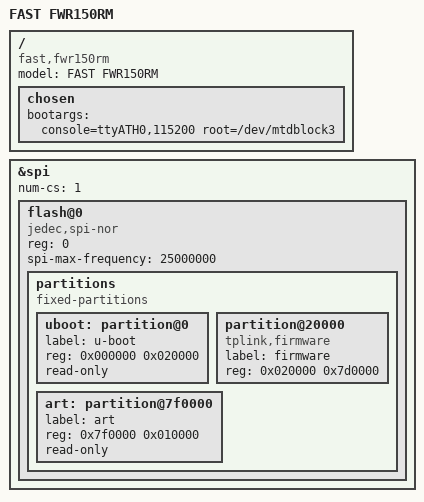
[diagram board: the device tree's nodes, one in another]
// SPDX-License-Identifier: GPL-2.0-or-later OR MIT

#include "ar9331_tplink_tl-wr710n.dtsi"

/ {
    model = "FAST FWR150RM";
    compatible = "fast,fwr150rm", "qca,ar9331";
    chosen {
        bootargs = "console=ttyATH0,115200 root=/dev/mtdblock3";
    };
};

&spi {
    status = "okay";
    num-cs = <1>;

    flash@0 {
        compatible = "jedec,spi-nor";
        reg = <0>;
        spi-max-frequency = <25000000>;
        partitions {
            compatible = "fixed-partitions";
            #address-cells = <1>;
            #size-cells = <1>;


            uboot:	partition@0 {
                label = "u-boot";
                reg = <0x000000 0x020000>;
                read-only;
            };

            partition@20000 {
                compatible = "tplink,firmware";
                label = "firmware";
                reg = <0x020000 0x7d0000>;
            };

            art: partition@7f0000 {
                label = "art";
                reg = <0x7f0000 0x010000>;
                read-only;
            };
        };
    };
};
